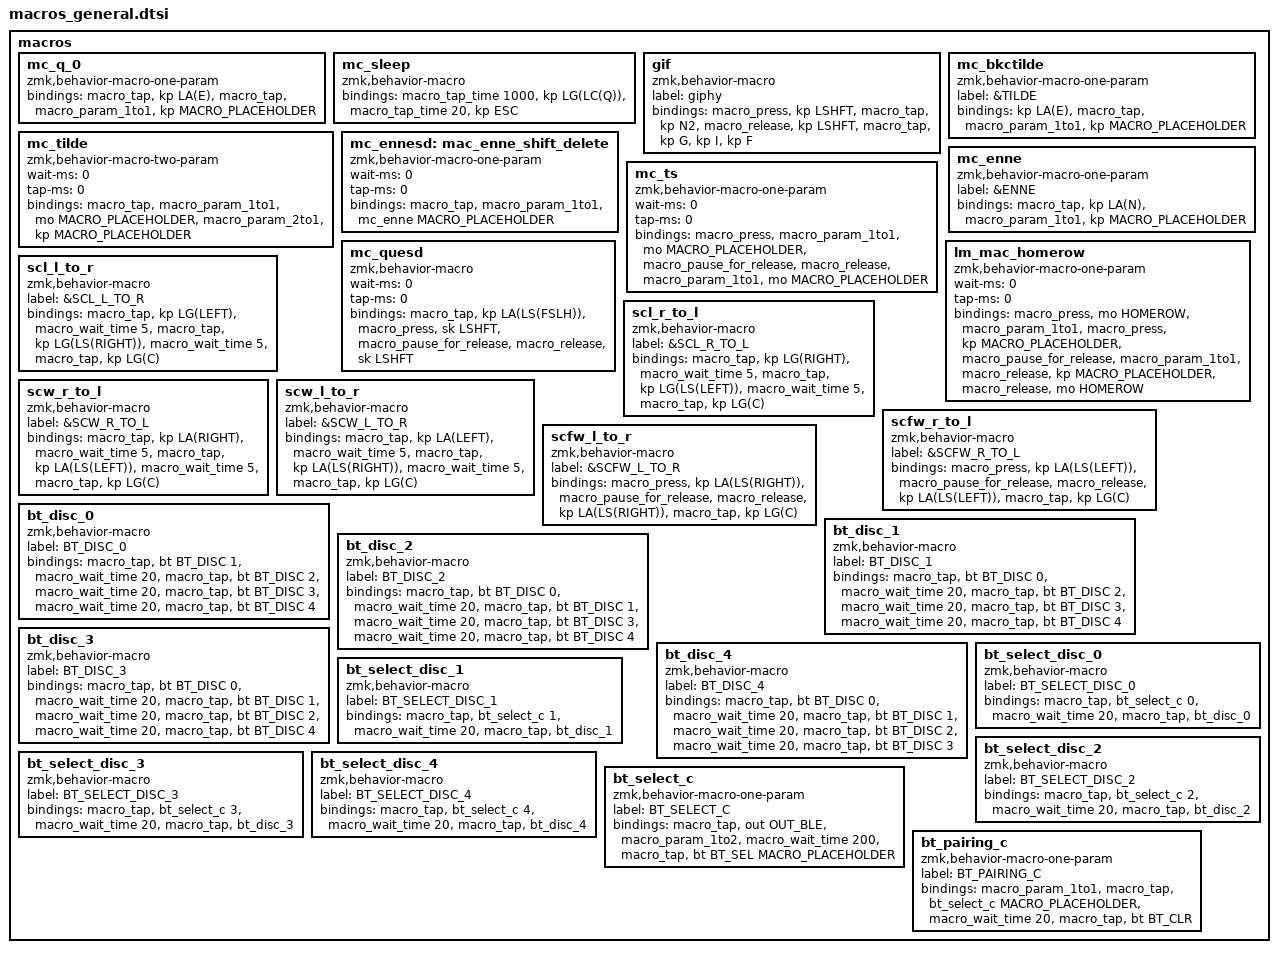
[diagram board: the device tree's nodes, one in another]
 macros {

        mc_q_0: mc_q_0 {
            compatible = "zmk,behavior-macro-one-param";
            #binding-cells = <1>;
            bindings =
                <&macro_tap>,
                <&kp LA(E)>,
                <&macro_tap>,
                <&macro_param_1to1 &kp MACRO_PLACEHOLDER>;
        };

        mc_sleep: mc_sleep {
            compatible = "zmk,behavior-macro";
            #binding-cells = <0>;
            bindings =
                <&macro_tap_time 1000>,
                <&kp LG(LC(Q))>,
                <&macro_tap_time 20>,
                <&kp ESC>;
        };

        gif: gif {
            label = "giphy";
            compatible = "zmk,behavior-macro";
            #binding-cells = <0>;
            bindings =
                <&macro_press>,
                <&kp LSHFT>,
                <&macro_tap>,
                <&kp N2>,
                <&macro_release>,
                <&kp LSHFT>,
                <&macro_tap>,
                <&kp G &kp I &kp F>;
        };

        // mc_bkctilde

        mc_bkctilde: mc_bkctilde {
            label = "&TILDE";
            compatible = "zmk,behavior-macro-one-param";
            #binding-cells = <1>;
            bindings =
                <&kp LA(E)>,
                <&macro_tap>,
                <&macro_param_1to1 &kp MACRO_PLACEHOLDER>;
        };

        mc_tilde: mc_tilde {
            compatible = "zmk,behavior-macro-two-param";
            wait-ms = <0>;
            tap-ms = <0>;
            #binding-cells = <2>;
            bindings =
                <&macro_tap>,
                <&macro_param_1to1 &mo MACRO_PLACEHOLDER>,
                <&macro_param_2to1 &kp MACRO_PLACEHOLDER>;
        };

        // mc_enne

        mc_enne: mc_enne {
            label = "&ENNE";
            compatible = "zmk,behavior-macro-one-param";
            #binding-cells = <1>;
            bindings =
                <&macro_tap>,
                <&kp LA(N) &macro_param_1to1 &kp MACRO_PLACEHOLDER>;
        };

        mc_ennesd: mac_enne_shift_delete {
            compatible = "zmk,behavior-macro-one-param";
            wait-ms = <0>;
            tap-ms = <0>;
            #binding-cells = <1>;
            bindings =
                <&macro_tap>,
                <&macro_param_1to1 &mc_enne MACRO_PLACEHOLDER>;
        };

        mc_ts: mc_ts {
            compatible = "zmk,behavior-macro-one-param";
            wait-ms = <0>;
            tap-ms = <0>;
            #binding-cells = <1>;
            bindings =
                <&macro_press>,
                <&macro_param_1to1 &mo MACRO_PLACEHOLDER>,
                <&macro_pause_for_release>,
                <&macro_release>,
                <&macro_param_1to1 &mo MACRO_PLACEHOLDER>;
        };

        mc_quesd: mc_quesd {
            compatible = "zmk,behavior-macro";
            wait-ms = <0>;
            tap-ms = <0>;
            #binding-cells = <0>;
            bindings =
                <&macro_tap>,
                <&kp LA(LS(FSLH))>,
                <&macro_press>,
                <&sk LSHFT>,
                <&macro_pause_for_release>,
                <&macro_release>,
                <&sk LSHFT>;
        };

        lm_mac_homerow: lm_mac_homerow {
            compatible = "zmk,behavior-macro-one-param";
            wait-ms = <0>;
            tap-ms = <0>;
            #binding-cells = <1>;
            bindings =
                <&macro_press>,
                <&mo HOMEROW &macro_param_1to1>,
                <&macro_press>,
                <&kp MACRO_PLACEHOLDER>,
                <&macro_pause_for_release>,
                <&macro_param_1to1>,
                <&macro_release>,
                <&kp MACRO_PLACEHOLDER>,
                <&macro_release>,
                <&mo HOMEROW>;
        };

        // Select a line copping from left to right

        scl_l_to_r: scl_l_to_r {
            label = "&SCL_L_TO_R";
            compatible = "zmk,behavior-macro";
            #binding-cells = <0>;
            bindings =
                <&macro_tap>,
                <&kp LG(LEFT)>,
                <&macro_wait_time 5>,
                <&macro_tap>,
                <&kp LG(LS(RIGHT))>,
                <&macro_wait_time 5>,
                <&macro_tap>,
                <&kp LG(C)>;
        };

        // Select a line copping from left to right

        scl_r_to_l: scl_r_to_l {
            label = "&SCL_R_TO_L";
            compatible = "zmk,behavior-macro";
            #binding-cells = <0>;
            bindings =
                <&macro_tap>,
                <&kp LG(RIGHT)>,
                <&macro_wait_time 5>,
                <&macro_tap>,
                <&kp LG(LS(LEFT))>,
                <&macro_wait_time 5>,
                <&macro_tap>,
                <&kp LG(C)>;
        };

        // Select a word from right to left

        scw_r_to_l: scw_r_to_l {
            label = "&SCW_R_TO_L";
            compatible = "zmk,behavior-macro";
            #binding-cells = <0>;
            bindings =
                <&macro_tap>,
                <&kp LA(RIGHT)>,
                <&macro_wait_time 5>,
                <&macro_tap>,
                <&kp LA(LS(LEFT))>,
                <&macro_wait_time 5>,
                <&macro_tap>,
                <&kp LG(C)>;
        };

        // Select a word from right to left

        scw_l_to_r: scw_l_to_r {
            label = "&SCW_L_TO_R";
            compatible = "zmk,behavior-macro";
            #binding-cells = <0>;
            bindings =
                <&macro_tap>,
                <&kp LA(LEFT)>,
                <&macro_wait_time 5>,
                <&macro_tap>,
                <&kp LA(LS(RIGHT))>,
                <&macro_wait_time 5>,
                <&macro_tap>,
                <&kp LG(C)>;
        };

        // Select and copy forward a word from right to left

        scfw_r_to_l: scfw_r_to_l {
            label = "&SCFW_R_TO_L";
            compatible = "zmk,behavior-macro";
            #binding-cells = <0>;
            bindings =
                <&macro_press>,
                <&kp LA(LS(LEFT))>,
                <&macro_pause_for_release>,
                <&macro_release>,
                <&kp LA(LS(LEFT))>,
                <&macro_tap>,
                <&kp LG(C)>;
        };

        // Select and copy forward a word from left to right

        scfw_l_to_r: scfw_l_to_r {
            label = "&SCFW_L_TO_R";
            compatible = "zmk,behavior-macro";
            #binding-cells = <0>;
            bindings =
                <&macro_press>,
                <&kp LA(LS(RIGHT))>,
                <&macro_pause_for_release>,
                <&macro_release>,
                <&kp LA(LS(RIGHT))>,
                <&macro_tap>,
                <&kp LG(C)>;
        };

        bt_disc_0: bt_disc_0 {
            label = "BT_DISC_0";
            compatible = "zmk,behavior-macro";
            #binding-cells = <0>;
            bindings =
                <&macro_tap>,
                <&bt BT_DISC 1>,
                <&macro_wait_time 20>,
                <&macro_tap>,
                <&bt BT_DISC 2>,
                <&macro_wait_time 20>,
                <&macro_tap>,
                <&bt BT_DISC 3>,
                <&macro_wait_time 20>,
                <&macro_tap>,
                <&bt BT_DISC 4>;
        };

        bt_disc_1: bt_disc_1 {
            label = "BT_DISC_1";
            compatible = "zmk,behavior-macro";
            #binding-cells = <0>;
            bindings =
                <&macro_tap>,
                <&bt BT_DISC 0>,
                <&macro_wait_time 20>,
                <&macro_tap>,
                <&bt BT_DISC 2>,
                <&macro_wait_time 20>,
                <&macro_tap>,
                <&bt BT_DISC 3>,
                <&macro_wait_time 20>,
                <&macro_tap>,
                <&bt BT_DISC 4>;
        };

        bt_disc_2: bt_disc_2 {
            label = "BT_DISC_2";
            compatible = "zmk,behavior-macro";
            #binding-cells = <0>;
            bindings =
                <&macro_tap>,
                <&bt BT_DISC 0>,
                <&macro_wait_time 20>,
                <&macro_tap>,
                <&bt BT_DISC 1>,
                <&macro_wait_time 20>,
                <&macro_tap>,
                <&bt BT_DISC 3>,
                <&macro_wait_time 20>,
                <&macro_tap>,
                <&bt BT_DISC 4>;
        };

        bt_disc_3: bt_disc_3 {
            label = "BT_DISC_3";
            compatible = "zmk,behavior-macro";
            #binding-cells = <0>;
            bindings =
                <&macro_tap>,
                <&bt BT_DISC 0>,
                <&macro_wait_time 20>,
                <&macro_tap>,
                <&bt BT_DISC 1>,
                <&macro_wait_time 20>,
                <&macro_tap>,
                <&bt BT_DISC 2>,
                <&macro_wait_time 20>,
                <&macro_tap>,
                <&bt BT_DISC 4>;
        };

        bt_disc_4: bt_disc_4 {
            label = "BT_DISC_4";
            compatible = "zmk,behavior-macro";
            #binding-cells = <0>;
            bindings =
                <&macro_tap>,
                <&bt BT_DISC 0>,
                <&macro_wait_time 20>,
                <&macro_tap>,
                <&bt BT_DISC 1>,
                <&macro_wait_time 20>,
                <&macro_tap>,
                <&bt BT_DISC 2>,
                <&macro_wait_time 20>,
                <&macro_tap>,
                <&bt BT_DISC 3>;
        };

        bt_select_disc_0: bt_select_disc_0 {
            label = "BT_SELECT_DISC_0";
            compatible = "zmk,behavior-macro";
            #binding-cells = <0>;
            bindings =
                <&macro_tap>,
                <&bt_select_c 0>,
                <&macro_wait_time 20>,
                <&macro_tap>,
                <&bt_disc_0>;
        };

        bt_select_disc_1: bt_select_disc_1 {
            label = "BT_SELECT_DISC_1";
            compatible = "zmk,behavior-macro";
            #binding-cells = <0>;
            bindings =
                <&macro_tap>,
                <&bt_select_c 1>,
                <&macro_wait_time 20>,
                <&macro_tap>,
                <&bt_disc_1>;
        };

        bt_select_disc_2: bt_select_disc_2 {
            label = "BT_SELECT_DISC_2";
            compatible = "zmk,behavior-macro";
            #binding-cells = <0>;
            bindings =
                <&macro_tap>,
                <&bt_select_c 2>,
                <&macro_wait_time 20>,
                <&macro_tap>,
                <&bt_disc_2>;
        };

        bt_select_disc_3: bt_select_disc_3 {
            label = "BT_SELECT_DISC_3";
            compatible = "zmk,behavior-macro";
            #binding-cells = <0>;
            bindings =
                <&macro_tap>,
                <&bt_select_c 3>,
                <&macro_wait_time 20>,
                <&macro_tap>,
                <&bt_disc_3>;
        };

        bt_select_disc_4: bt_select_disc_4 {
            label = "BT_SELECT_DISC_4";
            compatible = "zmk,behavior-macro";
            #binding-cells = <0>;
            bindings =
                <&macro_tap>,
                <&bt_select_c 4>,
                <&macro_wait_time 20>,
                <&macro_tap>,
                <&bt_disc_4>;
        };

        bt_select_c: bt_select_c {
            label = "BT_SELECT_C";
            compatible = "zmk,behavior-macro-one-param";
            #binding-cells = <1>;
            bindings =
                <&macro_tap>,
                <&out OUT_BLE &macro_param_1to2>,
                <&macro_wait_time 200>,
                <&macro_tap>,
                <&bt BT_SEL MACRO_PLACEHOLDER>;
        };

        bt_pairing_c: bt_pairing_c {
            label = "BT_PAIRING_C";
            compatible = "zmk,behavior-macro-one-param";
            #binding-cells = <1>;
            bindings =
                <&macro_param_1to1>,
                <&macro_tap>,
                <&bt_select_c MACRO_PLACEHOLDER>,
                <&macro_wait_time 20>,
                <&macro_tap>,
                <&bt BT_CLR>;
        };

    };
